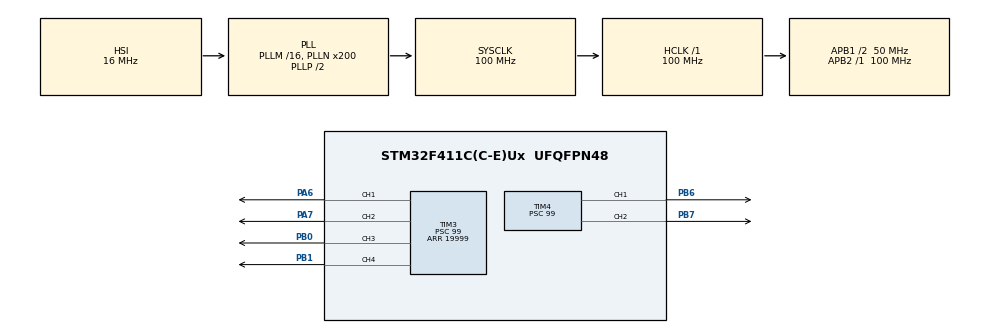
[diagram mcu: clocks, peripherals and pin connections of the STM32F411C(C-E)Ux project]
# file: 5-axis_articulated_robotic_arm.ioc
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Mcu.Family=STM32F4
Mcu.Name=STM32F411C(C-E)Ux
Mcu.Package=UFQFPN48
NVIC.PriorityGroup=NVIC_PRIORITYGROUP_4
PA13.Mode=Serial_Wire
PA13.Signal=SYS_JTMS-SWDIO
PA14.Mode=Serial_Wire
PA14.Signal=SYS_JTCK-SWCLK
PA6.Signal=S_TIM3_CH1
PA7.Signal=S_TIM3_CH2
PB0.Signal=S_TIM3_CH3
PB1.Signal=S_TIM3_CH4
PB6.Signal=S_TIM4_CH1
PB7.Signal=S_TIM4_CH2
ProjectManager.HeapSize=0x200
ProjectManager.StackSize=0x400
ProjectManager.TargetToolchain=CMake
RCC.48MHZClocksFreq_Value=50000000
RCC.AHBFreq_Value=100000000
RCC.APB1CLKDivider=RCC_HCLK_DIV2
RCC.APB1Freq_Value=50000000
RCC.APB1TimFreq_Value=100000000
RCC.APB2Freq_Value=100000000
RCC.APB2TimFreq_Value=100000000
RCC.CortexFreq_Value=100000000
RCC.HCLKFreq_Value=100000000
RCC.HSE_VALUE=25000000
RCC.HSI_VALUE=16000000
RCC.LSE_VALUE=32768
RCC.PLLN=200
RCC.SYSCLKFreq_VALUE=100000000
RCC.SYSCLKSource=RCC_SYSCLKSOURCE_PLLCLK
RCC.VCOOutputFreq_Value=200000000
SH.S_TIM3_CH1.0=TIM3_CH1,PWM Generation1 CH1
SH.S_TIM3_CH2.0=TIM3_CH2,PWM Generation2 CH2
SH.S_TIM3_CH3.0=TIM3_CH3,PWM Generation3 CH3
SH.S_TIM3_CH4.0=TIM3_CH4,PWM Generation4 CH4
SH.S_TIM4_CH1.0=TIM4_CH1,PWM Generation1 CH1
SH.S_TIM4_CH2.0=TIM4_CH2,PWM Generation2 CH2
TIM3.AutoReloadPreload=TIM_AUTORELOAD_PRELOAD_ENABLE
TIM3.Channel-PWM\ Generation1\ CH1=TIM_CHANNEL_1
TIM3.Channel-PWM\ Generation2\ CH2=TIM_CHANNEL_2
TIM3.Channel-PWM\ Generation3\ CH3=TIM_CHANNEL_3
TIM3.Channel-PWM\ Generation4\ CH4=TIM_CHANNEL_4
TIM3.Period=19999
TIM3.Prescaler=99
TIM3.Pulse-PWM\ Generation1\ CH1=1500
TIM3.Pulse-PWM\ Generation2\ CH2=1500
TIM3.Pulse-PWM\ Generation3\ CH3=1500
TIM3.Pulse-PWM\ Generation4\ CH4=1500
TIM4.AutoReloadPreload=TIM_AUTORELOAD_PRELOAD_ENABLE
TIM4.Channel-PWM\ Generation1\ CH1=TIM_CHANNEL_1
TIM4.Channel-PWM\ Generation2\ CH2=TIM_CHANNEL_2
TIM4.Period=19999
TIM4.Prescaler=99
TIM4.Pulse-PWM\ Generation1\ CH1=1500
TIM4.Pulse-PWM\ Generation2\ CH2=1500
board=custom

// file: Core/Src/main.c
/* USER CODE BEGIN Header */
/**
  ******************************************************************************
  * @file           : main.c
  * @brief          : Main program body
  ******************************************************************************
  * @attention
  *
  * Copyright (c) 2026 STMicroelectronics.
  * All rights reserved.
  *
  * This software is licensed under terms that can be found in the LICENSE file
  * in the root directory of this software component.
  * If no LICENSE file comes with this software, it is provided AS-IS.
  *
  ******************************************************************************
  */
/* USER CODE END Header */
#include "main.h"
#include "tim.h"
#include "gpio.h"

/* USER CODE BEGIN Includes */
#include "servo.h"
#include "bsp_servo_pwm.h"
/* USER CODE END Includes */

void SystemClock_Config(void);

int main(void)
{

  /* MCU Configuration--------------------------------------------------------*/

  /* Reset of all peripherals, Initializes the Flash interface and the Systick. */
  HAL_Init();

  /* Configure the system clock */
  SystemClock_Config();

  /* Initialize all configured peripherals */
  MX_GPIO_Init();
  MX_TIM3_Init();
  MX_TIM4_Init();
  /* USER CODE BEGIN 2 */
  Servo_Init();

  if (Servo_SetAngle(0U, 90.0f) != SERVO_OK) {
    Error_Handler();
  }

  if (BSP_ServoPWM_Start(0U) != BSP_SERVO_PWM_OK) {
    Error_Handler();
  }
  /* USER CODE END 2 */

  /* Infinite loop */
  while (1)
  {
    Servo_SetAngle(0U, 90.0f);
    HAL_Delay(2000U);

    Servo_SetAngle(0U, 100.0f);
    HAL_Delay(2000U);
  }
}

void SystemClock_Config(void)
{
  RCC_OscInitTypeDef RCC_OscInitStruct = {0};
  RCC_ClkInitTypeDef RCC_ClkInitStruct = {0};

  /** Configure the main internal regulator output voltage
  */
  __HAL_RCC_PWR_CLK_ENABLE();
  __HAL_PWR_VOLTAGESCALING_CONFIG(PWR_REGULATOR_VOLTAGE_SCALE1);

  /** Initializes the RCC Oscillators according to the specified parameters
  * in the RCC_OscInitTypeDef structure.
  */
  RCC_OscInitStruct.OscillatorType = RCC_OSCILLATORTYPE_HSI;
  RCC_OscInitStruct.HSIState = RCC_HSI_ON;
  RCC_OscInitStruct.HSICalibrationValue = RCC_HSICALIBRATION_DEFAULT;
  RCC_OscInitStruct.PLL.PLLState = RCC_PLL_ON;
  RCC_OscInitStruct.PLL.PLLSource = RCC_PLLSOURCE_HSI;
  RCC_OscInitStruct.PLL.PLLM = 16;
  RCC_OscInitStruct.PLL.PLLN = 200;
  RCC_OscInitStruct.PLL.PLLP = RCC_PLLP_DIV2;
  RCC_OscInitStruct.PLL.PLLQ = 4;
  if (HAL_RCC_OscConfig(&RCC_OscInitStruct) != HAL_OK)
  {
    Error_Handler();
  }

  /** Initializes the CPU, AHB and APB buses clocks
  */
  RCC_ClkInitStruct.ClockType = RCC_CLOCKTYPE_HCLK|RCC_CLOCKTYPE_SYSCLK
                              |RCC_CLOCKTYPE_PCLK1|RCC_CLOCKTYPE_PCLK2;
  RCC_ClkInitStruct.SYSCLKSource = RCC_SYSCLKSOURCE_PLLCLK;
  RCC_ClkInitStruct.AHBCLKDivider = RCC_SYSCLK_DIV1;
  RCC_ClkInitStruct.APB1CLKDivider = RCC_HCLK_DIV2;
  RCC_ClkInitStruct.APB2CLKDivider = RCC_HCLK_DIV1;

  if (HAL_RCC_ClockConfig(&RCC_ClkInitStruct, FLASH_LATENCY_3) != HAL_OK)
  {
    Error_Handler();
  }
}

void Error_Handler(void)
{
  __disable_irq();
  while (1)
  {
  }
}
